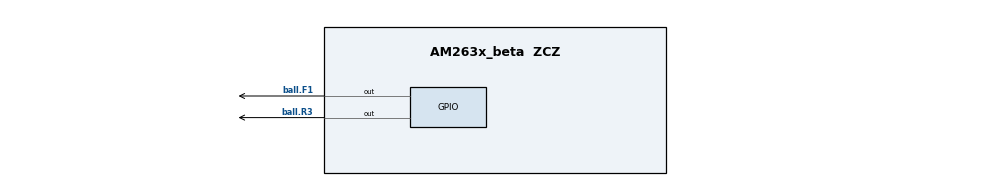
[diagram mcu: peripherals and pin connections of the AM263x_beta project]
/**
 * @cliArgs --device "AM263x_beta" --package "ZCZ" --part "AM263x" --context "r5fss0-0" --product "MCU_PLUS_SDK@07.03.01"
 * @versions {"tool":"1.14.0+2667"}
 */

/**
 * Import the modules used in this configuration.
 */
const gpio       = scripting.addModule("/drivers/gpio/gpio", {}, false);
const gpio1      = gpio.addInstance();
const gpio2      = gpio.addInstance();
const i2c        = scripting.addModule("/drivers/i2c/i2c", {}, false);
const i2c1       = i2c.addInstance();
const debug_log  = scripting.addModule("/kernel/dpl/debug_log");
const mpu_armv7  = scripting.addModule("/kernel/dpl/mpu_armv7", {}, false);
const mpu_armv71 = mpu_armv7.addInstance();
const mpu_armv72 = mpu_armv7.addInstance();
const mpu_armv73 = mpu_armv7.addInstance();
const mpu_armv74 = mpu_armv7.addInstance();
const mpu_armv75 = mpu_armv7.addInstance();

/**
 * Write custom configuration values to the imported modules.
 */
gpio1.$name                = "CONFIG_GPIO1";
gpio1.pinDir               = "OUTPUT";
gpio1.GPIO.$assign         = "GPIO0";
gpio1.GPIO.gpioPin.$assign = "ball.R3";

gpio2.$name                = "CONFIG_GPIO58";
gpio2.pinDir               = "OUTPUT";
gpio2.GPIO.$assign         = "GPIO0";
gpio2.GPIO.gpioPin.$assign = "ball.F1";

i2c1.$name           = "CONFIG_I2C0";
i2c1.I2C.$assign     = "I2C1";
i2c1.I2C.SCL.$assign = "ball.D7";
i2c1.I2C.SDA.$assign = "ball.C8";

debug_log.enableUartLog            = true;
debug_log.uartLog.$name            = "CONFIG_UART0";
debug_log.uartLog.UART.$assign     = "UART0";
debug_log.uartLog.UART.RXD.$assign = "ball.A7";
debug_log.uartLog.UART.TXD.$assign = "ball.A6";

mpu_armv71.$name             = "CONFIG_MPU_REGION0";
mpu_armv71.size              = 31;
mpu_armv71.attributes        = "Device";
mpu_armv71.accessPermissions = "Supervisor RD+WR, User RD";
mpu_armv71.allowExecute      = false;

mpu_armv72.$name             = "CONFIG_MPU_REGION1";
mpu_armv72.size              = 15;
mpu_armv72.accessPermissions = "Supervisor RD+WR, User RD";

mpu_armv73.$name             = "CONFIG_MPU_REGION2";
mpu_armv73.baseAddr          = 0x80000;
mpu_armv73.size              = 15;
mpu_armv73.accessPermissions = "Supervisor RD+WR, User RD";

mpu_armv74.$name             = "CONFIG_MPU_REGION3";
mpu_armv74.accessPermissions = "Supervisor RD+WR, User RD";
mpu_armv74.baseAddr          = 0x70000000;
mpu_armv74.size              = 21;

mpu_armv75.$name      = "CONFIG_MPU_REGION4";
mpu_armv75.baseAddr   = 0x70080000;
mpu_armv75.size       = 14;
mpu_armv75.attributes = "NonCached";
